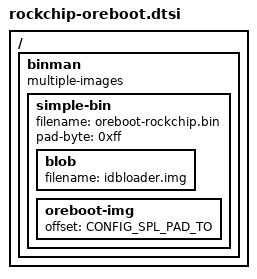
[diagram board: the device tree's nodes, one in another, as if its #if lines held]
// SPDX-License-Identifier: GPL-2.0+
/*
 * Copyright (C) 2019 Jagan Teki <jagan@amarulasolutions.com>
 */

/ {
	binman: binman {
		multiple-images;
	};
};

#ifdef CONFIG_SPL 
&binman {
	simple-bin {
		filename = "oreboot-rockchip.bin";
		pad-byte = <0xff>;

		blob {
			filename = "idbloader.img";
		};

		oreboot-img {
			offset = <CONFIG_SPL_PAD_TO>;
		};
	};
};
#endif
